# ATmega2560 register map
Vendor: Atmel; File version: 1.0
CPU: other r0p0, little endian, no MPU, no FPU, 4 interrupt priority bits
Registers are 8-bit, read-write, reset 0x0 unless marked. A register's access mark holds for its fields unless they carry their own. Offsets are from the block's base; [hi:lo] are bit positions; {n}, {i} and the like mark numbered series.

## JTAG — JTAG Interface
Base 0x00000051
0x00 OCDR — On-Chip Debug Related Register in I/O Memory
0x03 MCUSR — MCU Status Register
  [4] JTRF — JTAG Reset Flag
0x04 MCUCR — MCU Control Register
  [7] JTD — JTAG Interface Disable

## LOCKBIT — Lockbits
Base 0x00000000
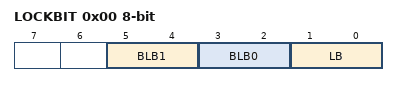
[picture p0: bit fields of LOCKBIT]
0x00 LOCKBIT
  [5:4] BLB1 — Boot Loader Protection Mode
    0=LPM_SPM_DISABLE (LPM and SPM prohibited in Boot Section); 1=LPM_DISABLE (LPM prohibited in Boot Section); 2=SPM_DISABLE (SPM prohibited in Boot Section); 3=NO_LOCK (No lock on SPM and LPM in Boot Section)
  [3:2] BLB0 — Boot Loader Protection Mode
    0=LPM_SPM_DISABLE (LPM and SPM prohibited in Application Section); 1=LPM_DISABLE (LPM prohibited in Application Section); 2=SPM_DISABLE (SPM prohibited in Application Section); 3=NO_LOCK (No lock on SPM and LPM in Application Section)
  [1:0] LB — Memory Lock
    0=PROG_VER_DISABLED (Further programming and verification disabled); 2=PROG_DISABLED (Further programming disabled); 3=NO_LOCK (No memory lock features enabled)

## PORTA — I/O Port
Base 0x00000020
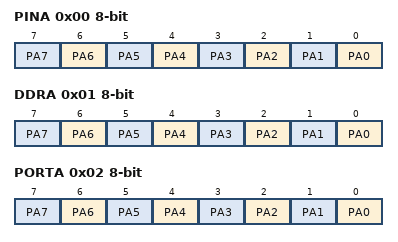
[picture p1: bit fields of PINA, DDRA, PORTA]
0x00 PINA — Port A Input Pins
  [n] PA{n} (n=0..7) — Pin A{n}
0x01 DDRA — Port A Data Direction Register
  [n] PA{n} (n=0..7) — Pin A{n}
0x02 PORTA — Port A Data Register
  [n] PA{n} (n=0..7) — Pin A{n}

## PORTB — I/O Port
Base 0x00000023
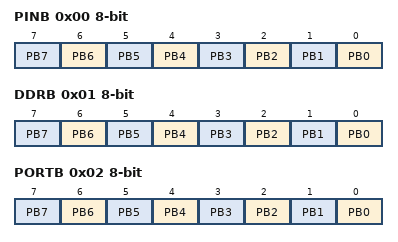
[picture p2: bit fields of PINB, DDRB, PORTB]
0x00 PINB — Port B Input Pins
  [n] PB{n} (n=0..7) — Pin B{n}
0x01 DDRB — Port B Data Direction Register
  [n] PB{n} (n=0..7) — Pin B{n}
0x02 PORTB — Port B Data Register
  [n] PB{n} (n=0..7) — Pin B{n}

## PORTC — I/O Port
Base 0x00000026
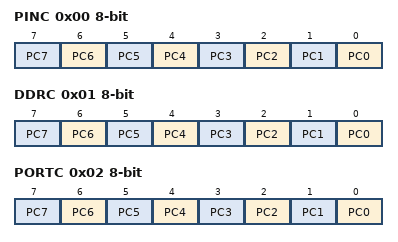
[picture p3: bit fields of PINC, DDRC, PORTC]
0x00 PINC — Port C Input Pins
  [n] PC{n} (n=0..7) — Pin C{n}
0x01 DDRC — Port C Data Direction Register
  [n] PC{n} (n=0..7) — Pin C{n}
0x02 PORTC — Port C Data Register
  [n] PC{n} (n=0..7) — Pin C{n}

## PORTD — I/O Port
Base 0x00000029
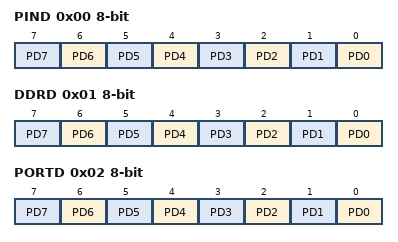
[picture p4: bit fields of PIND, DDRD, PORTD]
0x00 PIND — Port D Input Pins
  [n] PD{n} (n=0..7) — Pin D{n}
0x01 DDRD — Port D Data Direction Register
  [n] PD{n} (n=0..7) — Pin D{n}
0x02 PORTD — Port D Data Register
  [n] PD{n} (n=0..7) — Pin D{n}

## PORTE — I/O Port
Base 0x0000002C
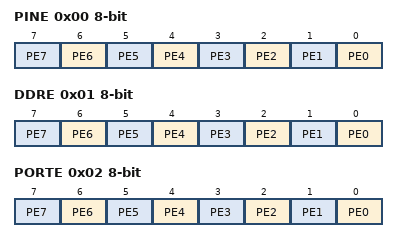
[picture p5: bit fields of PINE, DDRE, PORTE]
0x00 PINE — Input Pins, Port E
  [n] PE{n} (n=0..7) — Pin E{n}
0x01 DDRE — Data Direction Register, Port E
  [n] PE{n} (n=0..7) — Pin E{n}
0x02 PORTE — Data Register, Port E
  [n] PE{n} (n=0..7) — Pin E{n}

## PORTF — I/O Port
Base 0x0000002F
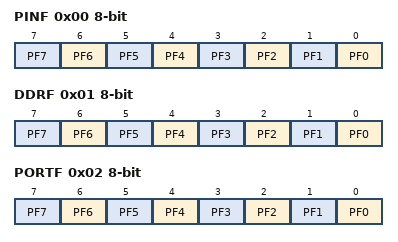
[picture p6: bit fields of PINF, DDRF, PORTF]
0x00 PINF — Input Pins, Port F
  [n] PF{n} (n=0..7) — Pin F{n}
0x01 DDRF — Data Direction Register, Port F
  [n] PF{n} (n=0..7) — Pin F{n}
0x02 PORTF — Data Register, Port F
  [n] PF{n} (n=0..7) — Pin F{n}

## PORTG — I/O Port
Base 0x00000032
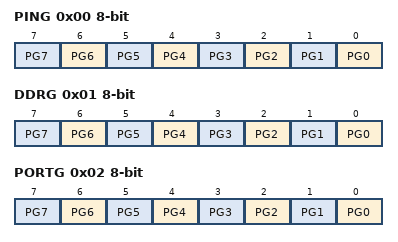
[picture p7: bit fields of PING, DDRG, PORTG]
0x00 PING — Input Pins, Port G
  [n] PG{n} (n=0..7) — Pin G{n}
0x01 DDRG — Data Direction Register, Port G
  [n] PG{n} (n=0..7) — Pin G{n}
0x02 PORTG — Data Register, Port G
  [n] PG{n} (n=0..7) — Pin G{n}

## PORTH — I/O Port
Base 0x00000100
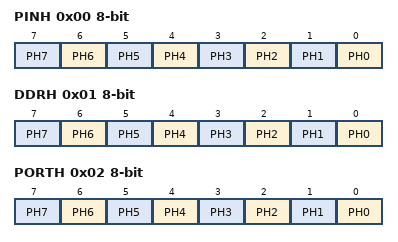
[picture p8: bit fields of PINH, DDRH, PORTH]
0x00 PINH — PORT H Input Pins
  [n] PH{n} (n=0..7) — Pin H{n}
0x01 DDRH — PORT H Data Direction Register
  [n] PH{n} (n=0..7) — Pin H{n}
0x02 PORTH — PORT H Data Register
  [n] PH{n} (n=0..7) — Pin H{n}

## PORTJ — I/O Port
Base 0x00000103
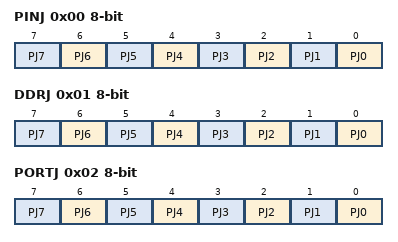
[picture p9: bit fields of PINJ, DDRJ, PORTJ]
0x00 PINJ — PORT J Input Pins
  [n] PJ{n} (n=0..7) — Pin J{n}
0x01 DDRJ — PORT J Data Direction Register
  [n] PJ{n} (n=0..7) — Pin J{n}
0x02 PORTJ — PORT J Data Register
  [n] PJ{n} (n=0..7) — Pin J{n}

## PORTK — I/O Port
Base 0x00000106
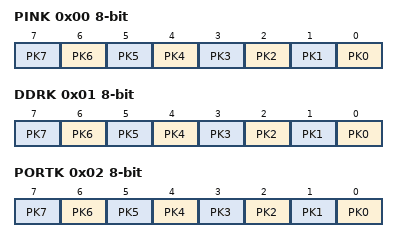
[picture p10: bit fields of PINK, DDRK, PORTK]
0x00 PINK — PORT K Input Pins
  [n] PK{n} (n=0..7) — Pin K{n}
0x01 DDRK — PORT K Data Direction Register
  [n] PK{n} (n=0..7) — Pin K{n}
0x02 PORTK — PORT K Data Register
  [n] PK{n} (n=0..7) — Pin K{n}
